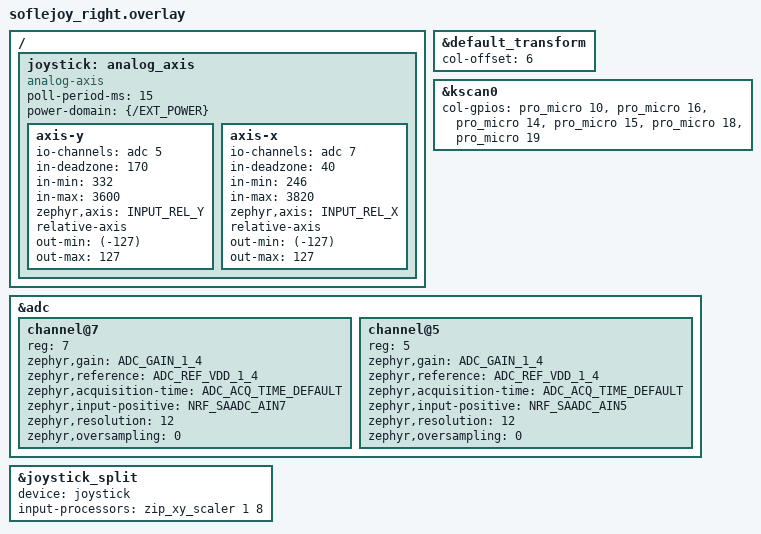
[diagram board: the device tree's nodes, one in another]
/*
 * Copyright (c) 2020 Ryan Cross
 *
 * SPDX-License-Identifier: MIT
 */

#include "soflejoy.dtsi"

#include <dt-bindings/zmk/input_transform.h>
#include <input/processors.dtsi>
#include <zephyr/dt-bindings/input/input-event-codes.h>

&default_transform {
    col-offset = <6>;
};

&kscan0 {
    col-gpios
        = <&pro_micro 10 GPIO_ACTIVE_HIGH>
        , <&pro_micro 16 GPIO_ACTIVE_HIGH>
        , <&pro_micro 14 GPIO_ACTIVE_HIGH>
        , <&pro_micro 15 GPIO_ACTIVE_HIGH>
        , <&pro_micro 18 GPIO_ACTIVE_HIGH>
        , <&pro_micro 19 GPIO_ACTIVE_HIGH>
        ;
};

/ { joystick: analog_axis {
        compatible = "analog-axis";
        poll-period-ms = <15>;
        power-domain = <&{/EXT_POWER}>;
        axis-y {
                io-channels = <&adc 5>;
                //in-deadzone = <300>;
                //in-min = <0>;
                //in-max = <4000>;
                in-deadzone = <170>;
                in-min = <332>;
                in-max = <3600>;
                zephyr,axis = <INPUT_REL_Y>;
                relative-axis;
                out-min = <(-127)>;
                out-max = <127>;
        };
        axis-x {
                io-channels = <&adc 7>;
                //in-deadzone = <300>;
                //in-min = <0>;
                //in-max = <4000>;
                in-deadzone = <40>;
                in-min = <246>;
                in-max = <3820>;
                zephyr,axis = <INPUT_REL_X>;
                relative-axis;
                out-min = <(-127)>;
                out-max = <127>;
        };
    };

    // this is a fix for axis hanging since there's nothing there anyway - for the real fix https://github.com/zephyrproject-rtos/zephyr/pull/74502, which has to be applied as a zephyr patch
    //chosen {
    //    /delete-property/ zmk,battery;
    //}; 
};


// configure the ADC for the joystick

&adc {
	#address-cells = <1>;
	#size-cells = <0>;
	channel@7 { // x -axis
		reg = <7>;
		zephyr,gain = "ADC_GAIN_1_4";
		zephyr,reference = "ADC_REF_VDD_1_4";
		zephyr,acquisition-time = <ADC_ACQ_TIME_DEFAULT>;
        zephyr,input-positive = <NRF_SAADC_AIN7>;
		zephyr,resolution = <12>;
		zephyr,oversampling = <0>;
	};
	channel@5 { // y-axis
		reg = <5>;
		zephyr,gain = "ADC_GAIN_1_4";
		zephyr,reference = "ADC_REF_VDD_1_4";
		zephyr,acquisition-time = <ADC_ACQ_TIME_DEFAULT>;
        zephyr,input-positive = <NRF_SAADC_AIN5>;
		zephyr,resolution = <12>;
		zephyr,oversampling = <0>;
	};
};

&joystick_split {
    device = <&joystick>;

    input-processors = <&zip_xy_scaler 1 8>;
};
